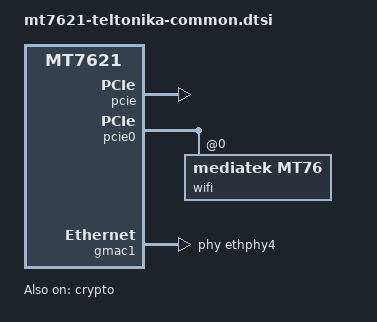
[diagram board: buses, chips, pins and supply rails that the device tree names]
#include <dt-bindings/input/input.h>
#include "mt7621.dtsi"
#include "platform_name.dtsi"

&pcie {
    status = "okay";
};

&pcie0 {
    wifi@0,0 {
        compatible = "mediatek,mt76";
        reg = <0x0000 0 0 0 0>;
        mediatek,mtd-eeprom = <&factory 0x0>;
    };
};

&gmac0 {
	nvmem-cells = <&macaddr_config_0 0>;
	nvmem-cell-names = "mac-address";
};

&gmac1 {
        status = "okay";
	label = "wan";
	phy-handle = <&ethphy4>;
	nvmem-cells = <&macaddr_config_0 1>;
	nvmem-cell-names = "mac-address";
};

&ethphy4 {
	/delete-property/ interrupts;
};

&crypto {
	status = "okay";
};
